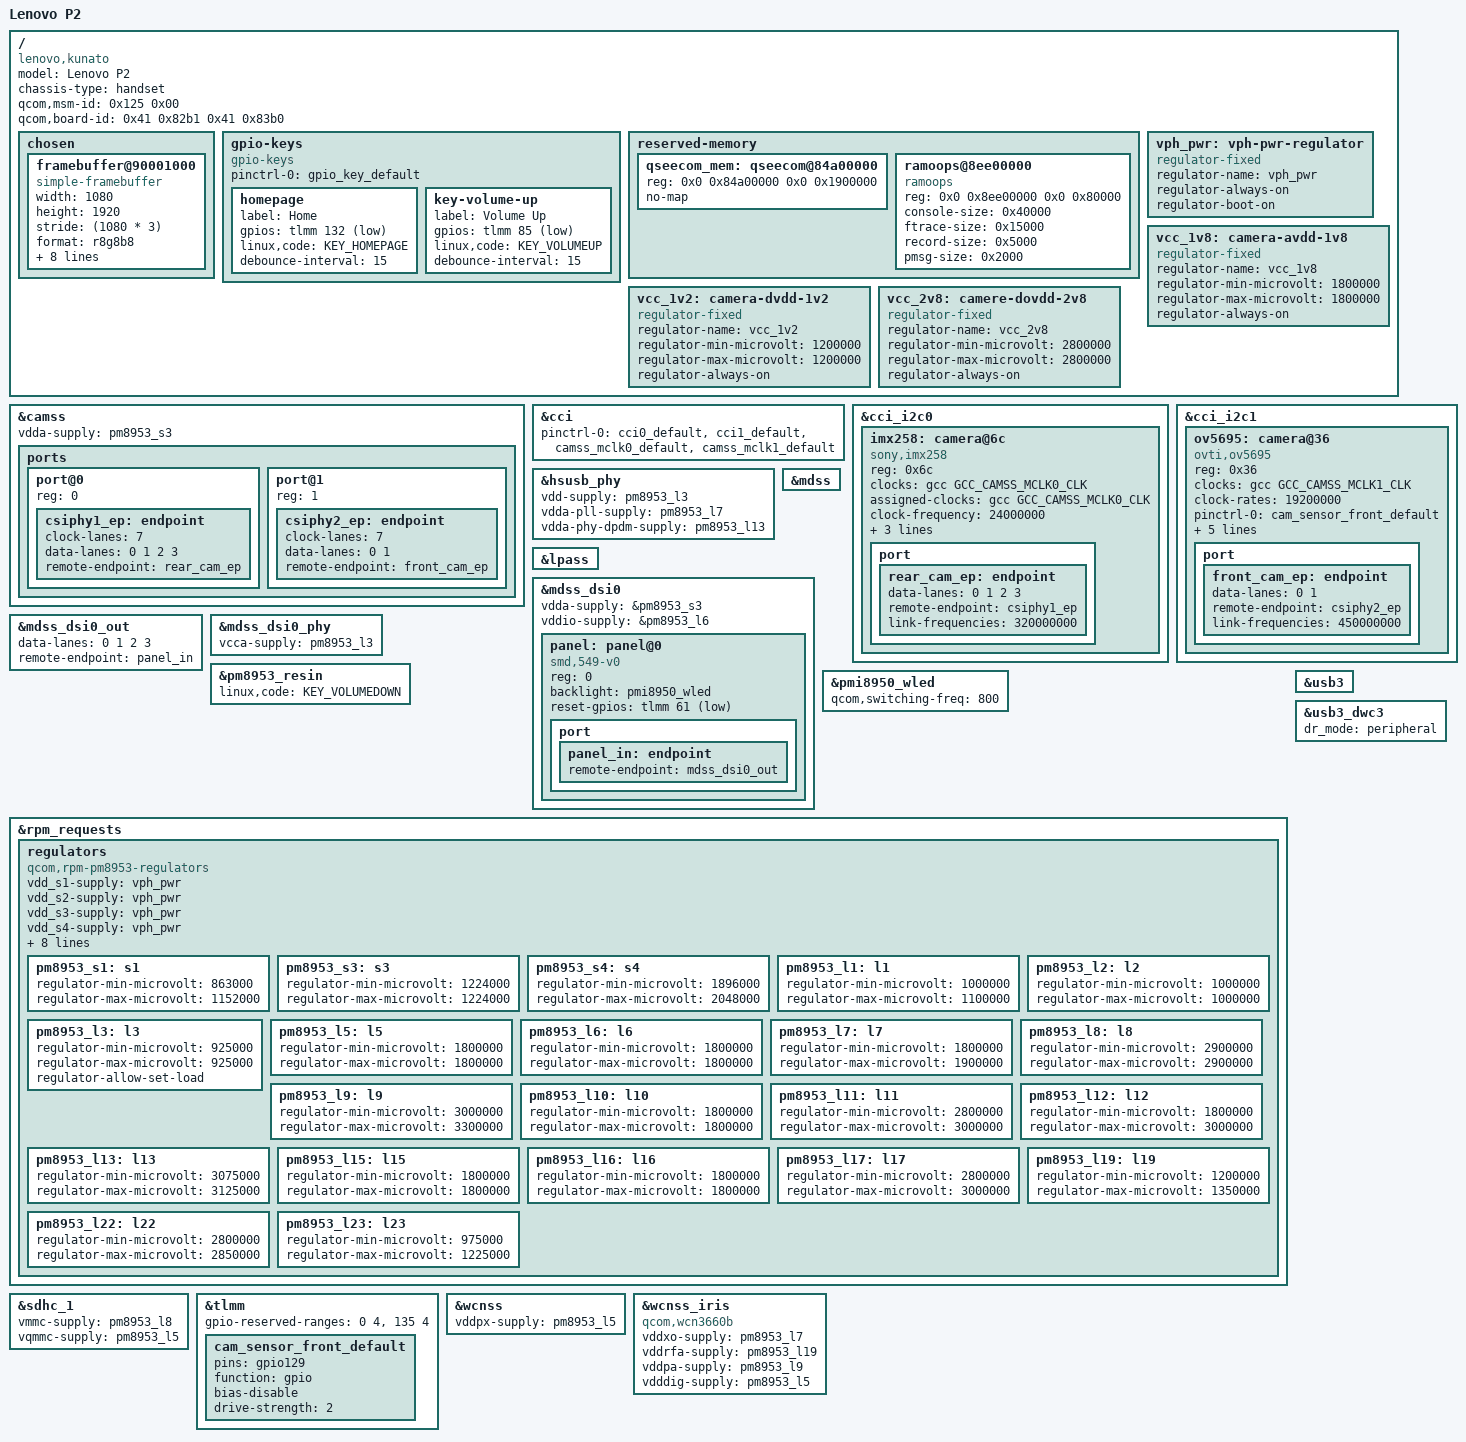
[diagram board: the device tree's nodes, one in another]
// SPDX-License-Identifier: GPL-2.0-only

/dts-v1/;

#include "msm8953.dtsi"
#include "pm8953.dtsi"
#include "pmi8950.dtsi"

/delete-node/ &qseecom_mem;

/ {
	model = "Lenovo P2";
	compatible = "lenovo,kunato", "qcom,msm8953";
	chassis-type = "handset";
	qcom,msm-id = <0x125 0x00>;
	qcom,board-id = <0x41 0x82b1 0x41 0x83b0>;

	chosen {
		#address-cells = <2>;
		#size-cells = <2>;
		ranges;

		framebuffer@90001000 {
			compatible = "simple-framebuffer";

			width = <1080>;
			height = <1920>;
			stride = <(1080 * 3)>;
			format = "r8g8b8";

			power-domains = <&gcc MDSS_GDSC>;

			clocks = <&gcc GCC_MDSS_AHB_CLK>,
				 <&gcc GCC_MDSS_AXI_CLK>,
				 <&gcc GCC_MDSS_VSYNC_CLK>,
				 <&gcc GCC_MDSS_MDP_CLK>,
				 <&gcc GCC_MDSS_BYTE0_CLK>,
				 <&gcc GCC_MDSS_PCLK0_CLK>,
				 <&gcc GCC_MDSS_ESC0_CLK>;
		};
	};

	gpio-keys {
		compatible = "gpio-keys";

		pinctrl-names = "default";
		pinctrl-0 = <&gpio_key_default>;

		homepage {
			label = "Home";
			gpios = <&tlmm 132 GPIO_ACTIVE_LOW>;
			linux,code = <KEY_HOMEPAGE>;
			debounce-interval = <15>;
		};

		key-volume-up {
			label = "Volume Up";
			gpios = <&tlmm 85 GPIO_ACTIVE_LOW>;
			linux,code = <KEY_VOLUMEUP>;
			debounce-interval = <15>;
		};
	};

	reserved-memory {
		qseecom_mem: qseecom@84a00000 {
			reg = <0x0 0x84a00000 0x0 0x1900000>;
			no-map;
		};

		ramoops@8ee00000 {
			compatible = "ramoops";
			reg = <0x0 0x8ee00000 0x0 0x80000>;
			console-size = <0x40000>;
			ftrace-size = <0x15000>;
			record-size = <0x5000>;
			pmsg-size = <0x2000>;
		};
	};

	vph_pwr: vph-pwr-regulator {
		compatible = "regulator-fixed";
		regulator-name = "vph_pwr";
		regulator-always-on;
		regulator-boot-on;
	};

	vcc_1v8: camera-avdd-1v8 {
		compatible = "regulator-fixed";
		regulator-name = "vcc_1v8";
		regulator-min-microvolt = <1800000>;
		regulator-max-microvolt = <1800000>;
		regulator-always-on;
	};

	vcc_1v2: camera-dvdd-1v2 {
		compatible = "regulator-fixed";
		regulator-name = "vcc_1v2";
		regulator-min-microvolt = <1200000>;
		regulator-max-microvolt = <1200000>;
		regulator-always-on;
	};

	vcc_2v8: camere-dovdd-2v8 {
		compatible = "regulator-fixed";
		regulator-name = "vcc_2v8";
		regulator-min-microvolt = <2800000>;
		regulator-max-microvolt = <2800000>;
		regulator-always-on;
	};
};

&camss {
	vdda-supply = <&pm8953_s3>;
	status = "okay";

	ports {
		port@0 {
			reg = <0>;
			csiphy1_ep: endpoint {
				clock-lanes = <7>;
				data-lanes = <0 1 2 3>;
				remote-endpoint = <&rear_cam_ep>;
			};
		};
		port@1 {
			reg = <1>;
			csiphy2_ep: endpoint {
				clock-lanes = <7>;
				data-lanes = <0 1>;
				remote-endpoint = <&front_cam_ep>;
			};
		};
	};
};

&cci {
	pinctrl-names = "default";
	pinctrl-0 = <&cci0_default>,
		    <&cci1_default>,
		    <&camss_mclk0_default>,
		    <&camss_mclk1_default>;

	status = "okay";
};

&cci_i2c0 {
	imx258: camera@6c {
		compatible = "sony,imx258";
		reg = <0x6c>;
		clocks = <&gcc GCC_CAMSS_MCLK0_CLK>;
		assigned-clocks = <&gcc GCC_CAMSS_MCLK0_CLK>;
		clock-frequency = <24000000>;

		vana-supply = <&pm8953_l12>;
		vdig-supply = <&pm8953_l23>;
		vif-supply = <&pm8953_l6>;

		port {
			rear_cam_ep: endpoint {
				data-lanes = <0 1 2 3>;
				remote-endpoint = <&csiphy1_ep>;
				link-frequencies = /bits/ 64 <320000000>;
			};
		};
	};
};

&cci_i2c1 {
	ov5695: camera@36 {
		compatible = "ovti,ov5695";
		reg = <0x36>;

		clocks = <&gcc GCC_CAMSS_MCLK1_CLK>;
		clock-names = "xvclk";
		clock-rates = <19200000>;

		pinctrl-0 = <&cam_sensor_front_default>;
		pinctrl-names = "default";

		reset-gpios = <&tlmm 129 GPIO_ACTIVE_LOW>;

		avdd-supply = <&vcc_1v8>;
		dvdd-supply = <&vcc_1v2>;
		dovdd-supply = <&vcc_2v8>;

		orientation = <0>;

		status = "okay";

		port {
			front_cam_ep: endpoint {
				data-lanes = <0 1>;
				remote-endpoint = <&csiphy2_ep>;
				link-frequencies = /bits/ 64 <450000000>;
			};
		};
	};
};

&hsusb_phy {
	vdd-supply = <&pm8953_l3>;
	vdda-pll-supply = <&pm8953_l7>;
	vdda-phy-dpdm-supply = <&pm8953_l13>;

	status = "okay";
};

&lpass {
	status = "okay";
};

&mdss {
	status = "okay";
};

&mdss_dsi0 {
	status = "okay";

	vdda-supply = "&pm8953_s3";
	vddio-supply = "&pm8953_l6";

    panel: panel@0 {
        compatible = "smd,549-v0";
        reg = <0>;

		backlight = <&pmi8950_wled>;
        reset-gpios = <&tlmm 61 GPIO_ACTIVE_LOW>;

        port {
            panel_in: endpoint {
                remote-endpoint = <&mdss_dsi0_out>;
            };
        };
    };
};

&mdss_dsi0_out {
    data-lanes = <0 1 2 3>;
    remote-endpoint = <&panel_in>;
};

&mdss_dsi0_phy {
	vcca-supply = <&pm8953_l3>;

	status = "okay";
};

&pm8953_resin {
	linux,code = <KEY_VOLUMEDOWN>;
	status = "okay";
};

&pmi8950_wled {
    qcom,switching-freq = <800>;
    status = "okay";
};

&rpm_requests {
	regulators {
		compatible = "qcom,rpm-pm8953-regulators";
		vdd_s1-supply = <&vph_pwr>;
		vdd_s2-supply = <&vph_pwr>;
		vdd_s3-supply = <&vph_pwr>;
		vdd_s4-supply = <&vph_pwr>;
		vdd_s5-supply = <&vph_pwr>;
		vdd_s6-supply = <&vph_pwr>;
		vdd_s7-supply = <&vph_pwr>;
		vdd_l1-supply = <&pm8953_s3>;
		vdd_l2_l3-supply = <&pm8953_s3>;
		vdd_l4_l5_l6_l7_l16_l19-supply = <&pm8953_s4>;
		vdd_l8_l11_l12_l13_l14_l15-supply = <&vph_pwr>;
		vdd_l9_l10_l17_l18_l22-supply = <&vph_pwr>;

		pm8953_s1: s1 {
			regulator-min-microvolt = <863000>;
			regulator-max-microvolt = <1152000>;
		};

		pm8953_s3: s3 {
			regulator-min-microvolt = <1224000>;
			regulator-max-microvolt = <1224000>;
		};

		pm8953_s4: s4 {
			regulator-min-microvolt = <1896000>;
			regulator-max-microvolt = <2048000>;
		};

		pm8953_l1: l1 {
			regulator-min-microvolt = <1000000>;
			regulator-max-microvolt = <1100000>;
		};

		pm8953_l2: l2 {
			regulator-min-microvolt = <1000000>;
			regulator-max-microvolt = <1000000>;
		};

		pm8953_l3: l3 {
			regulator-min-microvolt = <925000>;
			regulator-max-microvolt = <925000>;
			regulator-allow-set-load;
		};

		pm8953_l5: l5 {
			regulator-min-microvolt = <1800000>;
			regulator-max-microvolt = <1800000>;
		};

		pm8953_l6: l6 {
			regulator-min-microvolt = <1800000>;
			regulator-max-microvolt = <1800000>;
		};

		pm8953_l7: l7 {
			regulator-min-microvolt = <1800000>;
			regulator-max-microvolt = <1900000>;
		};

		pm8953_l8: l8 {
			regulator-min-microvolt = <2900000>;
			regulator-max-microvolt = <2900000>;
		};

		pm8953_l9: l9 {
			regulator-min-microvolt = <3000000>;
			regulator-max-microvolt = <3300000>;
		};

		pm8953_l10: l10 {
			regulator-min-microvolt = <1800000>;
			regulator-max-microvolt = <1800000>;
		};

		pm8953_l11: l11 {
			regulator-min-microvolt = <2800000>;
			regulator-max-microvolt = <3000000>;
		};

		pm8953_l12: l12 {
			regulator-min-microvolt = <1800000>;
			regulator-max-microvolt = <3000000>;
		};

		pm8953_l13: l13 {
			regulator-min-microvolt = <3075000>;
			regulator-max-microvolt = <3125000>;
		};

		pm8953_l15: l15 {
			regulator-min-microvolt = <1800000>;
			regulator-max-microvolt = <1800000>;
		};

		pm8953_l16: l16 {
			regulator-min-microvolt = <1800000>;
			regulator-max-microvolt = <1800000>;
		};

		pm8953_l17: l17 {
			regulator-min-microvolt = <2800000>;
			regulator-max-microvolt = <3000000>;
		};

		pm8953_l19: l19 {
			regulator-min-microvolt = <1200000>;
			regulator-max-microvolt = <1350000>;
		};

		pm8953_l22: l22 {
			regulator-min-microvolt = <2800000>;
			regulator-max-microvolt = <2850000>;
		};

		pm8953_l23: l23 {
			regulator-min-microvolt = <975000>;
			regulator-max-microvolt = <1225000>;
		};
	};
};

&sdhc_1 {
	vmmc-supply = <&pm8953_l8>;
	vqmmc-supply = <&pm8953_l5>;

	status = "okay";
};

&usb3 {
	status = "okay";
};

&usb3_dwc3 {
	dr_mode = "peripheral";
};

&tlmm {
	gpio-reserved-ranges = <0 4>, <135 4>;

	cam_sensor_front_default: cam_sensor_front_default {
		pins = "gpio129";
		function = "gpio";
		bias-disable;
		drive-strength = <2>;
	};
};

&wcnss {
	vddpx-supply = <&pm8953_l5>;

	status = "okay";
};

&wcnss_iris {
	compatible = "qcom,wcn3660b";

	vddxo-supply = <&pm8953_l7>;
	vddrfa-supply = <&pm8953_l19>;
	vddpa-supply = <&pm8953_l9>;
	vdddig-supply = <&pm8953_l5>;
};
